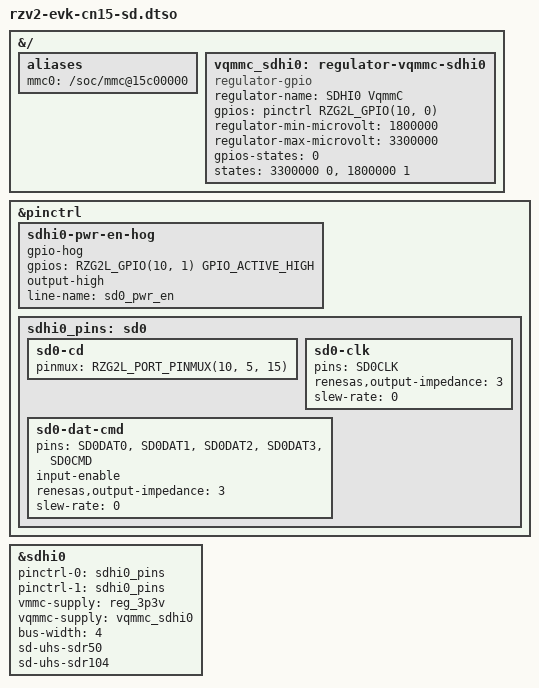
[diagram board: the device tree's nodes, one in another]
// SPDX-License-Identifier: GPL-2.0
/*
 * Shared DT overlay for the microSD Sub Board (RTK0EF0186B01000BJ), which
 * is connected to the CN15 connector on the RZ/V2H and RZ/V2N EVKs.
 *
 * Copyright (C) 2025 Renesas Electronics Corp.
 */

/dts-v1/;
/plugin/;

#include <dt-bindings/gpio/gpio.h>
#include <dt-bindings/pinctrl/rzg2l-pinctrl.h>

&{/} {
	aliases {
		mmc0 = "/soc/mmc@15c00000";
	};

	vqmmc_sdhi0: regulator-vqmmc-sdhi0 {
		compatible = "regulator-gpio";
		regulator-name = "SDHI0 VqmmC";
		gpios = <&pinctrl RZG2L_GPIO(10, 0) GPIO_ACTIVE_HIGH>;
		regulator-min-microvolt = <1800000>;
		regulator-max-microvolt = <3300000>;
		gpios-states = <0>;
		states = <3300000 0>, <1800000 1>;
	};
};

&pinctrl {
	sdhi0-pwr-en-hog {
		gpio-hog;
		gpios = <RZG2L_GPIO(10, 1) GPIO_ACTIVE_HIGH>;
		output-high;
		line-name = "sd0_pwr_en";
	};

	sdhi0_pins: sd0 {
		sd0-cd {
			pinmux = <RZG2L_PORT_PINMUX(10, 5, 15)>; /* SD0_CD */
		};

		sd0-clk {
			pins = "SD0CLK";
			renesas,output-impedance = <3>;
			slew-rate = <0>;
		};

		sd0-dat-cmd {
			pins = "SD0DAT0", "SD0DAT1", "SD0DAT2", "SD0DAT3", "SD0CMD";
			input-enable;
			renesas,output-impedance = <3>;
			slew-rate = <0>;
		};
	};
};

&sdhi0 {
	pinctrl-0 = <&sdhi0_pins>;
	pinctrl-1 = <&sdhi0_pins>;
	pinctrl-names = "default", "state_uhs";
	vmmc-supply = <&reg_3p3v>;
	vqmmc-supply = <&vqmmc_sdhi0>;
	bus-width = <4>;
	sd-uhs-sdr50;
	sd-uhs-sdr104;
	status = "okay";
};
